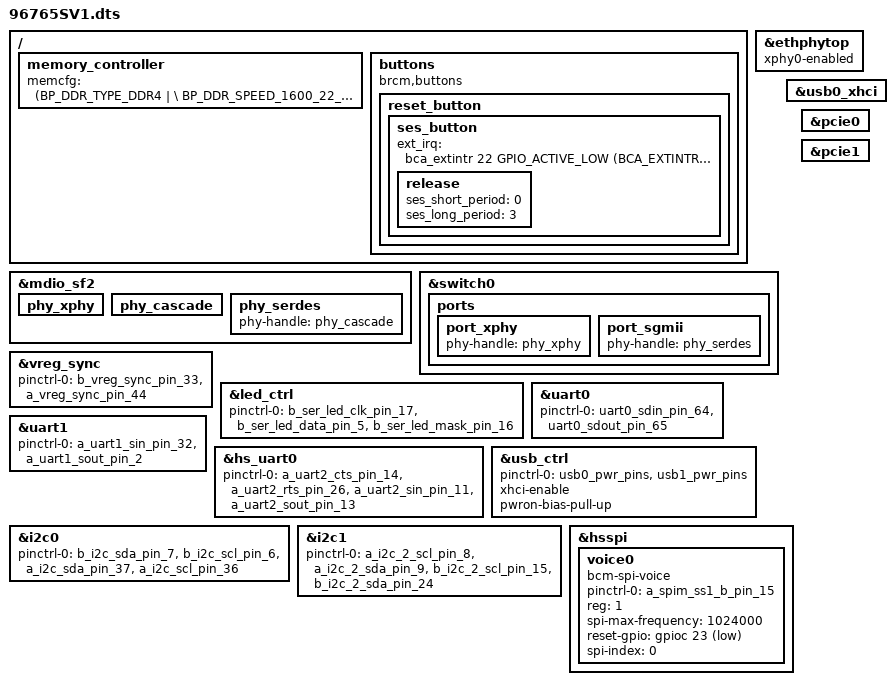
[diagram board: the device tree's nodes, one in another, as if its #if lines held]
#include "6765.dtsi"

/ {

	memory_controller {
		memcfg = <(BP_DDR_TYPE_DDR4       | \
			BP_DDR_SPEED_1600_22_22_22    | \
			BP_DDR_TOTAL_SIZE_4096MB      | \
			BP_DDR_DEVICE_WIDTH_8         | \
			BP_DDR_TOTAL_WIDTH_16BIT      | \
			BP_DDR_6765_DEFAULT           | \
			BP_DDR_CONFIG_DEBUG)>;
	};
	buttons {
		compatible = "brcm,buttons";
		reset_button {
			ses_button {
				ext_irq = <&bca_extintr 22 GPIO_ACTIVE_LOW (BCA_EXTINTR_TYPE_LOW_LEVEL | BCA_EXTINTR_TYPE_SENSE_EDGE)>;
				release {
					ses_short_period = <0>;
					ses_long_period = <3>;
				};
			};
		};
	};

};


&mdio_sf2 {
       /* Port PHY mapping:
            port_imp -8#0- port_xhy <----> phy_xphy
                      # #
                      ##5- port_sgmii <-> phy_serdes - phy_cascade
         */
	phy_xphy {
		status = "okay";
	};
	phy_cascade {
		status = "okay";
	};
	phy_serdes {
		phy-handle = <&phy_cascade>;
		status = "okay";
	};
};

&ethphytop {
    xphy0-enabled;
    status = "okay";
};

&switch0 {

	ports {
		port_xphy {
			phy-handle = <&phy_xphy>;
			status = "okay";
		};
		port_sgmii {
			phy-handle = <&phy_serdes>;
			status = "okay";
		};
	};
};

&vreg_sync {
	pinctrl-0 = <&b_vreg_sync_pin_33 &a_vreg_sync_pin_44>;
	pinctrl-names = "default";
	status="okay";
};

&led_ctrl {
	pinctrl-names = "default";
	pinctrl-0 = <&b_ser_led_clk_pin_17 &b_ser_led_data_pin_5 &b_ser_led_mask_pin_16>;
};
&uart0 {
    pinctrl-names = "default";
    pinctrl-0 = <&uart0_sdin_pin_64 &uart0_sdout_pin_65>;
    status = "okay";
};
&uart1 {
    pinctrl-names = "default";
    pinctrl-0 = <&a_uart1_sin_pin_32 &a_uart1_sout_pin_2>;
    status = "okay";
};
&hs_uart0 {
	pinctrl-0 = <&a_uart2_cts_pin_14 &a_uart2_rts_pin_26 &a_uart2_sin_pin_11 &a_uart2_sout_pin_13>;
	pinctrl-names = "default";
	status = "okay";
};
&usb_ctrl {
	pinctrl-names="default";
	pinctrl-0 = <&usb0_pwr_pins &usb1_pwr_pins>;
	status = "okay";
	xhci-enable;
	pwron-bias-pull-up;
};

&usb0_xhci {
	status = "okay";
};

&i2c0 {
	pinctrl-names = "default";
	pinctrl-0 = <&b_i2c_sda_pin_7 &b_i2c_scl_pin_6 &a_i2c_sda_pin_37 &a_i2c_scl_pin_36 >;
	status = "okay";
};

&i2c1 {
	pinctrl-names = "default";
	pinctrl-0 = <&a_i2c_2_scl_pin_8 &a_i2c_2_sda_pin_9 &b_i2c_2_scl_pin_15 &b_i2c_2_sda_pin_24>;
	status = "okay";
};

&hsspi {
	status = "okay";
	voice0 {
		pinctrl-0 = <&a_spim_ss1_b_pin_15>;
		pinctrl-names = "default";
		compatible = "bcm-spi-voice";
		reg = <1>; /* chip select 1 */
		spi-max-frequency = <1024000>;
		reset-gpio = <&gpioc 23 GPIO_ACTIVE_LOW>;
		spi-index = <0>;/* voice header index */
	};
};

#if defined(CONFIG_BCM_PCIE_HCD) || defined (CONFIG_BCM_PCIE_HCD_MODULE)
&pcie0 {
	status = "okay";
};

&pcie1 {
	status = "okay";
};
#endif
